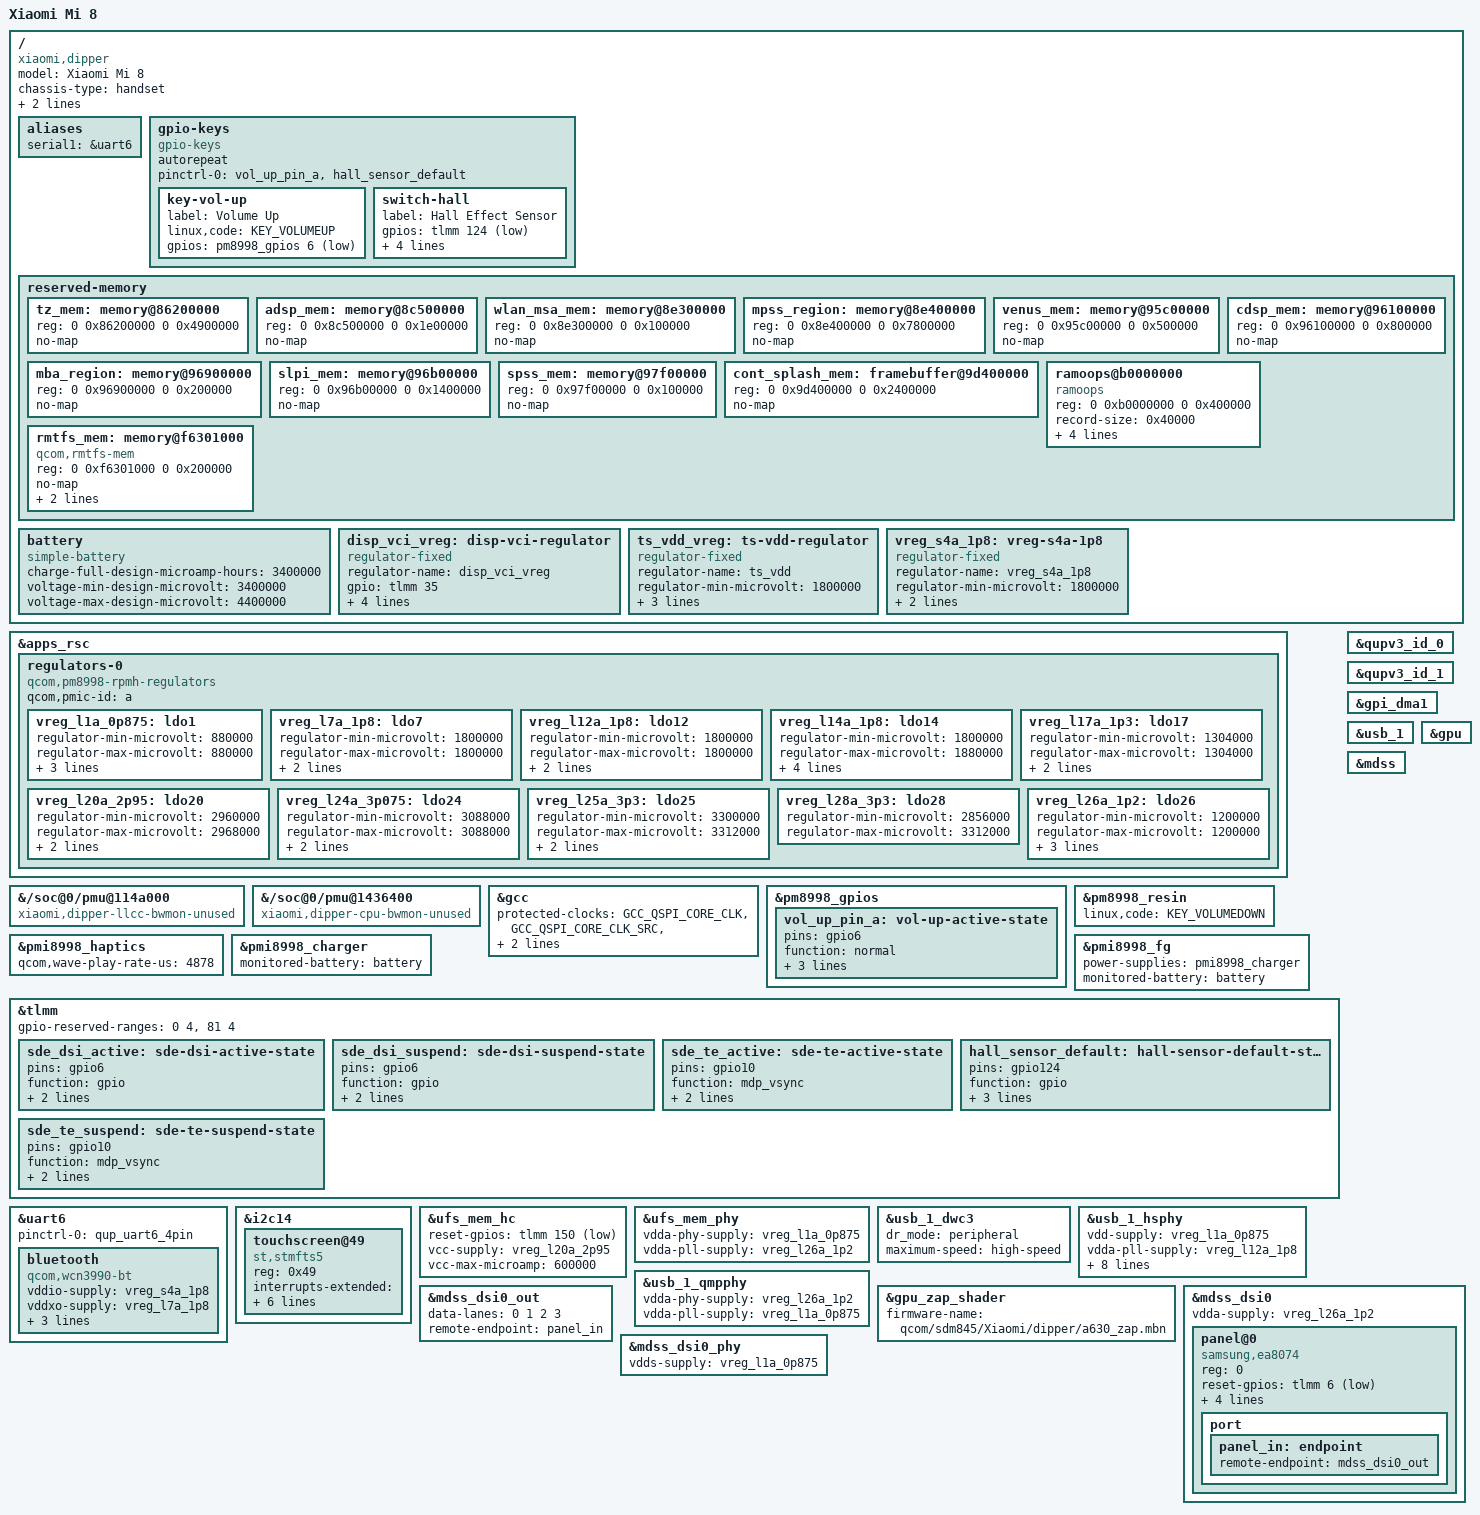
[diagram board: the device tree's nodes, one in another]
// SPDX-License-Identifier: GPL-2.0
/*
 * Minimal headless device tree for the Xiaomi Mi 8 (dipper).
 *
 * Built against sdm845-mainline (sdm845-7.1-rc1-r0). Derived from
 * sdm845-xiaomi-beryllium-common.dtsi (same SoC and PMICs); values were
 * checked against the downstream dipper DT (LineageOS lineage-21) and the
 * reserved-memory map printed by the stock MIUI kernel on this phone.
 *
 * Enabled: CPU, UFS, USB (peripheral, for USB networking), RPMh regulators,
 * buttons and hall sensor, haptics, Bluetooth (WCN3990 on UART6), the GPU
 * (Adreno 630), the touchscreen (ST FTS5 on i2c14), the PMI8998 charger and
 * fuel gauge, and the display (Samsung EA8074 cmd-mode panel on DSI0; needs
 * the panel-samsung-ea8074 driver). The modem, Wi-Fi, DSPs, audio and
 * cameras are left disabled: this unit has a failed RF transceiver and the
 * modem crash-loops if started.
 */

/dts-v1/;

#include <dt-bindings/arm/qcom,ids.h>
#include <dt-bindings/input/input.h>
#include <dt-bindings/pinctrl/qcom,pmic-gpio.h>
#include <dt-bindings/regulator/qcom,rpmh-regulator.h>
#include "sdm845.dtsi"
#include "pm8998.dtsi"
#include "pmi8998.dtsi"

/*
 * Firmware carve-outs differ from upstream sdm845.dtsi; the addresses below
 * match what the stock kernel reserved on this phone.
 */
/delete-node/ &tz_mem;
/delete-node/ &adsp_mem;
/delete-node/ &wlan_msa_mem;
/delete-node/ &mpss_region;
/delete-node/ &venus_mem;
/delete-node/ &cdsp_mem;
/delete-node/ &mba_region;
/delete-node/ &slpi_mem;
/delete-node/ &spss_mem;
/delete-node/ &rmtfs_mem;

/ {
	model = "Xiaomi Mi 8";
	compatible = "xiaomi,dipper", "qcom,sdm845";
	chassis-type = "handset";

	/* required for bootloader to select correct board */
	qcom,board-id = <55 0>;
	qcom,msm-id = <QCOM_ID_SDM845 0x20001>;

	aliases {
		serial1 = &uart6;
	};

	gpio-keys {
		compatible = "gpio-keys";
		autorepeat;

		pinctrl-names = "default";
		pinctrl-0 = <&vol_up_pin_a &hall_sensor_default>;

		key-vol-up {
			label = "Volume Up";
			linux,code = <KEY_VOLUMEUP>;
			gpios = <&pm8998_gpios 6 GPIO_ACTIVE_LOW>;
		};

		/* Magnetic cover sensor, "hall_key" on GPIO 124 downstream */
		switch-hall {
			label = "Hall Effect Sensor";
			gpios = <&tlmm 124 GPIO_ACTIVE_LOW>;
			linux,input-type = <EV_SW>;
			linux,code = <SW_LID>;
			linux,can-disable;
			wakeup-source;
		};
	};

	reserved-memory {
		tz_mem: memory@86200000 {
			reg = <0 0x86200000 0 0x4900000>;
			no-map;
		};

		adsp_mem: memory@8c500000 {
			reg = <0 0x8c500000 0 0x1e00000>;
			no-map;
		};

		wlan_msa_mem: memory@8e300000 {
			reg = <0 0x8e300000 0 0x100000>;
			no-map;
		};

		mpss_region: memory@8e400000 {
			reg = <0 0x8e400000 0 0x7800000>;
			no-map;
		};

		venus_mem: memory@95c00000 {
			reg = <0 0x95c00000 0 0x500000>;
			no-map;
		};

		cdsp_mem: memory@96100000 {
			reg = <0 0x96100000 0 0x800000>;
			no-map;
		};

		mba_region: memory@96900000 {
			reg = <0 0x96900000 0 0x200000>;
			no-map;
		};

		slpi_mem: memory@96b00000 {
			reg = <0 0x96b00000 0 0x1400000>;
			no-map;
		};

		spss_mem: memory@97f00000 {
			reg = <0 0x97f00000 0 0x100000>;
			no-map;
		};

		/* Cont splash region set up by the bootloader */
		cont_splash_mem: framebuffer@9d400000 {
			reg = <0 0x9d400000 0 0x2400000>;
			no-map;
		};

		/*
		 * Same location and layout as the stock/TWRP kernels, so a
		 * console log left here survives a warm reset and can be read
		 * from /sys/fs/pstore in TWRP.
		 */
		ramoops@b0000000 {
			compatible = "ramoops";
			reg = <0 0xb0000000 0 0x400000>;
			record-size = <0x40000>;
			console-size = <0x40000>;
			ftrace-size = <0x40000>;
			pmsg-size = <0x200000>;
			ecc-size = <0>;
		};

		rmtfs_mem: memory@f6301000 {
			compatible = "qcom,rmtfs-mem";
			reg = <0 0xf6301000 0 0x200000>;
			no-map;

			qcom,client-id = <1>;
			qcom,vmid = <QCOM_SCM_VMID_MSS_MSA>;
		};
	};

	battery: battery {
		compatible = "simple-battery";

		/* 3400 mAh pack, 4.4 V float (downstream batterydata) */
		charge-full-design-microamp-hours = <3400000>;
		voltage-min-design-microvolt = <3400000>;
		voltage-max-design-microvolt = <4400000>;
	};

	/* Panel vci (3.0 V), switched by GPIO 35 per the downstream DT */
	disp_vci_vreg: disp-vci-regulator {
		compatible = "regulator-fixed";
		regulator-name = "disp_vci_vreg";
		gpio = <&tlmm 35 GPIO_ACTIVE_HIGH>;
		enable-active-high;
		startup-delay-us = <4000>;
		regulator-boot-on;
		regulator-always-on;
	};

	/* Touch controller vdd (1.8 V), "disp_vddio_vreg" on GPIO 23 downstream */
	ts_vdd_vreg: ts-vdd-regulator {
		compatible = "regulator-fixed";
		regulator-name = "ts_vdd";
		regulator-min-microvolt = <1800000>;
		regulator-max-microvolt = <1800000>;
		gpio = <&tlmm 23 GPIO_ACTIVE_HIGH>;
		enable-active-high;
	};

	vreg_s4a_1p8: vreg-s4a-1p8 {
		compatible = "regulator-fixed";
		regulator-name = "vreg_s4a_1p8";

		regulator-min-microvolt = <1800000>;
		regulator-max-microvolt = <1800000>;
		regulator-always-on;
	};
};

/* Only the rails used by UFS and USB; values match downstream dipper */
&apps_rsc {
	regulators-0 {
		compatible = "qcom,pm8998-rpmh-regulators";
		qcom,pmic-id = "a";

		vreg_l1a_0p875: ldo1 {
			regulator-min-microvolt = <880000>;
			regulator-max-microvolt = <880000>;
			regulator-initial-mode = <RPMH_REGULATOR_MODE_HPM>;
			regulator-boot-on;
		};

		vreg_l7a_1p8: ldo7 {
			regulator-min-microvolt = <1800000>;
			regulator-max-microvolt = <1800000>;
			regulator-initial-mode = <RPMH_REGULATOR_MODE_HPM>;
		};

		vreg_l12a_1p8: ldo12 {
			regulator-min-microvolt = <1800000>;
			regulator-max-microvolt = <1800000>;
			regulator-initial-mode = <RPMH_REGULATOR_MODE_HPM>;
		};

		/*
		 * Panel vddio. Left on by the bootloader (downstream proxy
		 * consumer).
		 */
		vreg_l14a_1p8: ldo14 {
			regulator-min-microvolt = <1800000>;
			regulator-max-microvolt = <1880000>;
			regulator-initial-mode = <RPMH_REGULATOR_MODE_HPM>;
			regulator-boot-on;
			regulator-always-on;
		};

		vreg_l17a_1p3: ldo17 {
			regulator-min-microvolt = <1304000>;
			regulator-max-microvolt = <1304000>;
			regulator-initial-mode = <RPMH_REGULATOR_MODE_HPM>;
		};

		vreg_l20a_2p95: ldo20 {
			regulator-min-microvolt = <2960000>;
			regulator-max-microvolt = <2968000>;
			regulator-initial-mode = <RPMH_REGULATOR_MODE_HPM>;
		};

		vreg_l24a_3p075: ldo24 {
			regulator-min-microvolt = <3088000>;
			regulator-max-microvolt = <3088000>;
			regulator-initial-mode = <RPMH_REGULATOR_MODE_HPM>;
		};

		vreg_l25a_3p3: ldo25 {
			regulator-min-microvolt = <3300000>;
			regulator-max-microvolt = <3312000>;
			regulator-initial-mode = <RPMH_REGULATOR_MODE_HPM>;
		};

		/*
		 * Touch avdd. Keep it a range with no initial mode, so nothing is
		 * sent to RPMh for it until the touch driver enables it: a fixed
		 * 3.3 V boot-on/always-on HPM description stopped the boot before
		 * USB came up.
		 */
		vreg_l28a_3p3: ldo28 {
			regulator-min-microvolt = <2856000>;
			regulator-max-microvolt = <3312000>;
		};

		vreg_l26a_1p2: ldo26 {
			regulator-min-microvolt = <1200000>;
			regulator-max-microvolt = <1200000>;
			regulator-initial-mode = <RPMH_REGULATOR_MODE_HPM>;
			regulator-boot-on;
		};
	};
};

/*
 * Keep the gladiator/memory NoC interconnect providers from reaching
 * sync_state(). When they do, the bootloader's bandwidth votes are dropped
 * and the next cluster power collapse (cluster_sleep_0) hard-hangs this
 * phone, ~16 s into boot. The CPU/LLCC bandwidth monitors are their last
 * consumers: leave the nodes enabled (so fw_devlink keeps waiting for them)
 * but with a compatible no driver binds. Disabling them instead makes the
 * sync happen even earlier. TODO: find the path that needs a sleep vote.
 */
&{/soc@0/pmu@114a000} {
	compatible = "xiaomi,dipper-llcc-bwmon-unused";
};

&{/soc@0/pmu@1436400} {
	compatible = "xiaomi,dipper-cpu-bwmon-unused";
};

&gcc {
	protected-clocks = <GCC_QSPI_CORE_CLK>,
			   <GCC_QSPI_CORE_CLK_SRC>,
			   <GCC_QSPI_CNOC_PERIPH_AHB_CLK>,
			   <GCC_LPASS_Q6_AXI_CLK>,
			   <GCC_LPASS_SWAY_CLK>;
};

&pm8998_gpios {
	vol_up_pin_a: vol-up-active-state {
		pins = "gpio6";
		function = "normal";
		input-enable;
		bias-pull-up;
		qcom,drive-strength = <PMIC_GPIO_STRENGTH_NO>;
	};
};

&pm8998_resin {
	linux,code = <KEY_VOLUMEDOWN>;
	status = "okay";
};

/* LRA vibrator; play rate from the downstream DT (same as beryllium) */
&pmi8998_haptics {
	qcom,wave-play-rate-us = <4878>;
	status = "okay";
};

&pmi8998_charger {
	monitored-battery = <&battery>;
	status = "okay";
};

&pmi8998_fg {
	power-supplies = <&pmi8998_charger>;
	monitored-battery = <&battery>;
	status = "okay";
};

/*
 * GPIOs 0-3 and 81-84 are owned by TrustZone (fingerprint/eSE SPI) on all
 * Xiaomi SDM845 boards; touching their TLMM registers faults the kernel
 * before USB comes up. Same ranges as beryllium, polaris and equuleus.
 */
&tlmm {
	gpio-reserved-ranges = <0 4>, <81 4>;
};

&qupv3_id_0 {
	status = "okay";
};

/* WCN3990 Bluetooth; independent of the (dead) modem, unlike its Wi-Fi */
&uart6 {
	pinctrl-0 = <&qup_uart6_4pin>;
	status = "okay";

	bluetooth {
		compatible = "qcom,wcn3990-bt";

		vddio-supply = <&vreg_s4a_1p8>;
		vddxo-supply = <&vreg_l7a_1p8>;
		vddrf-supply = <&vreg_l17a_1p3>;
		vddch0-supply = <&vreg_l25a_3p3>;
		max-speed = <3200000>;
	};
};

&qupv3_id_1 {
	status = "okay";
};

&gpi_dma1 {
	status = "okay";
};

&i2c14 {
	status = "okay";

	/* ST FingerTip FTS5 ("st,fts" downstream), stmfts driver */
	touchscreen@49 {
		compatible = "st,stmfts5";
		reg = <0x49>;
		interrupts-extended = <&tlmm 31 IRQ_TYPE_LEVEL_LOW>;
		avdd-supply = <&vreg_l28a_3p3>;
		vdd-supply = <&ts_vdd_vreg>;
		reset-gpios = <&tlmm 32 GPIO_ACTIVE_LOW>;
		touchscreen-size-x = <1080>;
		touchscreen-size-y = <2248>;
	};
};

&ufs_mem_hc {
	status = "okay";

	reset-gpios = <&tlmm 150 GPIO_ACTIVE_LOW>;

	vcc-supply = <&vreg_l20a_2p95>;
	vcc-max-microamp = <600000>;
};

&ufs_mem_phy {
	status = "okay";

	vdda-phy-supply = <&vreg_l1a_0p875>;
	vdda-pll-supply = <&vreg_l26a_1p2>;
};

&usb_1 {
	status = "okay";
};

&usb_1_dwc3 {
	dr_mode = "peripheral";
	/* downstream dipper also runs this port at high speed only */
	maximum-speed = "high-speed";
};

&usb_1_hsphy {
	status = "okay";

	vdd-supply = <&vreg_l1a_0p875>;
	vdda-pll-supply = <&vreg_l12a_1p8>;
	vdda-phy-dpdm-supply = <&vreg_l24a_3p075>;

	qcom,imp-res-offset-value = <8>;
	qcom,hstx-trim-value = <QUSB2_V2_HSTX_TRIM_21_6_MA>;
	qcom,preemphasis-level = <QUSB2_V2_PREEMPHASIS_5_PERCENT>;
	qcom,preemphasis-width = <QUSB2_V2_PREEMPHASIS_WIDTH_HALF_BIT>;
};

/* Referenced by usb_1_dwc3; downstream dipper enables it as well */
&usb_1_qmpphy {
	status = "okay";

	vdda-phy-supply = <&vreg_l26a_1p2>;
	vdda-pll-supply = <&vreg_l1a_0p875>;
};

/* Adreno 630; the zap shader is Xiaomi-signed (vendor/firmware/a630_zap.elf) */
&gpu {
	status = "okay";
};

&gpu_zap_shader {
	firmware-name = "qcom/sdm845/Xiaomi/dipper/a630_zap.mbn";
};

&mdss {
	status = "okay";
};

&mdss_dsi0 {
	vdda-supply = <&vreg_l26a_1p2>;
	status = "okay";

	panel@0 {
		compatible = "samsung,ea8074";
		reg = <0>;

		reset-gpios = <&tlmm 6 GPIO_ACTIVE_LOW>;
		vddio-supply = <&vreg_l14a_1p8>;
		vci-supply = <&disp_vci_vreg>;

		pinctrl-0 = <&sde_dsi_active &sde_te_active>;
		pinctrl-1 = <&sde_dsi_suspend &sde_te_suspend>;
		pinctrl-names = "default", "sleep";

		port {
			panel_in: endpoint {
				remote-endpoint = <&mdss_dsi0_out>;
			};
		};
	};
};

&mdss_dsi0_out {
	data-lanes = <0 1 2 3>;
	remote-endpoint = <&panel_in>;
};

&mdss_dsi0_phy {
	vdds-supply = <&vreg_l1a_0p875>;
	status = "okay";
};

&tlmm {
	sde_dsi_active: sde-dsi-active-state {
		pins = "gpio6";
		function = "gpio";
		drive-strength = <8>;
		bias-disable;
	};

	sde_dsi_suspend: sde-dsi-suspend-state {
		pins = "gpio6";
		function = "gpio";
		drive-strength = <2>;
		bias-pull-down;
	};

	sde_te_active: sde-te-active-state {
		pins = "gpio10";
		function = "mdp_vsync";
		drive-strength = <2>;
		bias-pull-down;
	};

	hall_sensor_default: hall-sensor-default-state {
		pins = "gpio124";
		function = "gpio";
		drive-strength = <2>;
		bias-disable;
		input-enable;
	};

	sde_te_suspend: sde-te-suspend-state {
		pins = "gpio10";
		function = "mdp_vsync";
		drive-strength = <2>;
		bias-pull-down;
	};
};
